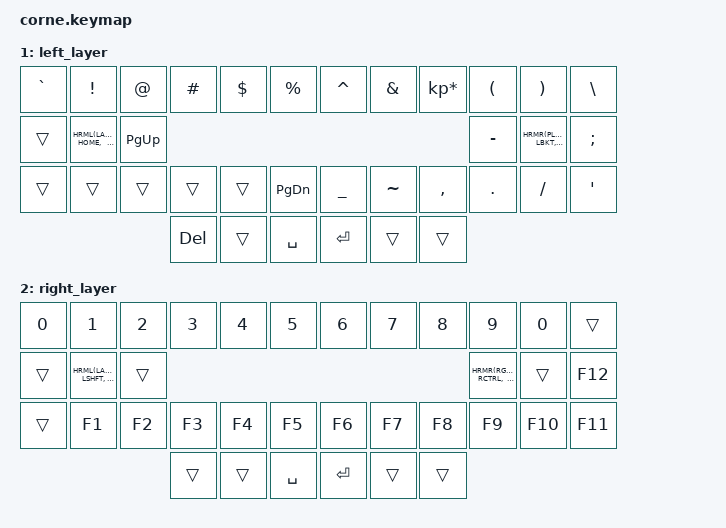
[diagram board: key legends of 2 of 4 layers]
/*
 * Copyright (c) 2020 The ZMK Contributors
 *
 * SPDX-License-Identifier: MIT
 */

#include <behaviors.dtsi>
#include <dt-bindings/zmk/keys.h>
#include <dt-bindings/zmk/bt.h>

#define L_DEFAULT 0
#define L_LEFT    1
#define L_RIGHT   2
#define L_SPECIAL 3

#define HRML(k1, k2, k3, k4) &ht LALT k1  &ht LCTRL k2  &ht LSHFT k3  &ht LGUI k4
#define HRMR(k1, k2, k3, k4) &ht RGUI k1  &ht RSHFT k2  &ht RCTRL k3  &ht RALT k4
#define HRMRR(k1, k2, k3) &ht RGUI k1  &ht RSHFT k2  &ht RCTRL k3
//#define LRTL(k) &layert L_LEFT k

&key_repeat {
	usage-pages = <HID_USAGE_KEY HID_USAGE_CONSUMER>;
};

/ {
    	behaviors {
        	ht: hold_tap {
            		compatible = "zmk,behavior-hold-tap";
            		label = "HOLD_TAP";
            		#binding-cells = <2>;
            		flavor = "tap-preferred";
            		tapping-term-ms = <220>;
            		quick-tap-ms = <150>;
			global-quick-tap;
            		bindings = <&kp>, <&kp>;
        	};
/*
        	layert: layer_tap {
            		compatible = "zmk,behavior-hold-tap";
            		label = "LAYER_TAP";
            		#binding-cells = <2>;
            		flavor = "tap-preferred";
            		tapping-term-ms = <220>;
            		quick-tap-ms = <150>;
			global-quick-tap;
            		bindings = <&mo>, <&kp>;
        	};
*/
                td_rep: tap_dance_repeat {
                        compatible = "zmk,behavior-tap-dance";
                        label = "TD_REPEAT";
                        #binding-cells = <0>;
                        tapping-term-ms = <220>;
                        bindings = <&kp RCTRL>, <&key_repeat>;
                };
                td_gui: tap_dance_gui {
                        compatible = "zmk,behavior-tap-dance";
                        label = "TD_GUI";
                        #binding-cells = <0>;
                        tapping-term-ms = <300>;
                        bindings = <&kp LGUI>, <&mo L_SPECIAL>;
                };
                td_l: tap_dance_l {
                        compatible = "zmk,behavior-tap-dance";
                        label = "TD_LEFT";
                        #binding-cells = <0>;
                        tapping-term-ms = <300>;
                        bindings = <&mo L_LEFT>, <&mo L_SPECIAL>;
                };
                td_r: tap_dance_r {
                        compatible = "zmk,behavior-tap-dance";
                        label = "TD_RIGHT";
                        #binding-cells = <0>;
                        tapping-term-ms = <300>;
                        bindings = <&mo L_RIGHT>, <&mo L_SPECIAL>;
                };
                td_caps: tap_dance_caps {
                        compatible = "zmk,behavior-tap-dance";
                        label = "TD_CAPS_LOCK";
                        #binding-cells = <0>;
                        tapping-term-ms = <300>;
                        bindings = <&kp LSHFT>, <&kp CAPS>;
                };

    	};

    	combos {
        	compatible = "zmk,combos";
	        combo_esc0 {
            		timeout-ms = <50>;
            		key-positions = <0 1>;
            		bindings = <&kp ESC>;
        	};
	        combo_esc1 {
            		timeout-ms = <50>;
            		key-positions = <1 2>;
            		bindings = <&kp ESC>;
        	};
		combo_esc2 {
            		timeout-ms = <50>;
            		key-positions = <4 5>;
            		bindings = <&kp ESC>;
        	};
    	};

/*
    	macros {
        	macro_n: macro_n {
	            label = "MACRO_N";
        	    compatible = "zmk,behavior-macro";
	            #binding-cells = <0>;
        	    bindings
	                = <&macro_press &kp RALT>
			, <&macro_tap &kp N>
			, <&macro_release &kp RALT>
			, <&macro_tap &kp N>
	                ;
        	};
        	macro_tilde: macro_tilde {
	            label = "MACRO_TILDE";
        	    compatible = "zmk,behavior-macro";
	            #binding-cells = <0>;
        	    bindings
	                = <&macro_press &kp RALT>
			, <&macro_tap &kp E>
			, <&macro_release &kp RALT>
	                ;
        	};
        	macro_0: macro_0 {
	            label = "MACRO_0";
        	    compatible = "zmk,behavior-macro";
	            #binding-cells = <0>;
        	    bindings
	                = <&macro_press &kp LGUI>
			, <&macro_tap &kp GRAVE>
			, <&macro_release &kp LGUI>
	                ;
        	};
        	macro_vim_w: macro_vim_w {
	            label = "MACRO_W";
        	    compatible = "zmk,behavior-macro";
	            #binding-cells = <0>;
        	    bindings
	                = <&macro_tap &kp COLON>
			, <&macro_tap &kp W>
	                ;
        	};
        	macro_vim_q: macro_vim_q {
	            label = "MACRO_Q";
        	    compatible = "zmk,behavior-macro";
	            #binding-cells = <0>;
        	    bindings
	                = <&macro_tap &kp COLON>
			, <&macro_tap &kp Q>
	                ;
        	};

	};
*/

        keymap {
                compatible = "zmk,keymap";

                default_layer {
                        bindings = <
//  ----------------------------------------------------------     --------------------------------------------------------------------
// |   TAB     |  Q     |  W     |  E      |  R     |  T      |   |  Y     |  U      |  I         |  O        |  P          | \        |                        
     &kp TAB      &kp Q   &kp W     &kp E     &kp R    &kp T         &kp Y    &kp U     &kp I        &kp O       &kp P        &kp BSLH
// |----------------------------------------------------------     --------------------------------------------------------------------|
// | SHIFT / CAPS |  A  |  S     |  D      |  F     |  G      |   |  H     |  J      |  K         |  L        |  UP         |  ;       |
     &td_caps    HRML(A,   S,       D,        F)       &kp G         &kp H   HRMRR(J,    K,           L)         &kp UP       &kp SEMI
// |----------------------------------------------------------     --------------------------------------------------------------------|   
// | CTRL      |  Z     |  X     |  C      |  V     |  B      |   |  N     |  M      |  ,         |  LEFT     | DOWN        | RIGHT    |
     &td_rep     &kp Z    &kp X    &kp C     &kp V    &kp B         &kp N    &kp M     &kp COMMA     &kp LEFT    &kp DOWN     &kp RIGHT
// |----------------------------------------------------------     --------------------------------------------------------------------|     
//                          | GUI / SPECIAL | LAYERS | SPC    |   | ENT    | LAYERS  | BSPC      |
                                  &td_gui     &td_l   &kp SPACE    &kp RET  &td_r     &kp BSPC
                        >;
                };

                left_layer {
                        bindings = <
//  ----------------------------------------------------------------------     -------------------------------------------------------------------------  
// |  `          |  !        |  @       |  #       |  $       |  %        |   |  ^        |  &       |  *              |  (       |  )       |  \       |                        
      &kp GRAVE     &kp EXCL    &kp AT    &kp HASH   &kp DLLR   &kp PRCNT       &kp CARET   &kp AMPS   &kp KP_MULTIPLY   &kp LPAR   &kp RPAR   &kp BSLH
//  ----------------------------------------------------------------------     -------------------------------------------------------------------------      
// |             |           |          | HOME     | END      | PAGE_UP   |   |  -        |  +       |  =              |  [       |  ]       | ;        |
     &trans     HRML(LALT,      LCTRL,    HOME,      END)       &kp PG_UP       &kp MINUS  HRMR(PLUS,   EQUAL,            LBKT,      RBKT)     &kp SEMI
//  ----------------------------------------------------------------------     -------------------------------------------------------------------------     
// |             |           |          |          |          | PAGE_DOWN |   |  _        |  ~       |  ,              |  .       |  /       |  '       |
     &trans         &trans      &trans    &trans     &trans     &kp PG_DN       &kp UNDER   &kp TILDE   &kp COMMA         &kp DOT   &kp FSLH   &kp SQT
//  ----------------------------------------------------------------------     -------------------------------------------------------------------------        
//                                      | DEL      | XXXXXXX  | SPC       |   | ENT       |          |                 |   
                    	                  &kp DEL    &trans     &kp SPACE       &kp RET     &trans     &trans
                        >;
                };

                right_layer {
                        bindings = <
//  ----------------------------------------------------------------------     -----------------------------------------------------------------  
// |  0         |  1        |  2        |  3      |  4        |  5        |   | 6        |  7       |  8       |  9        |  0      |          |
      &kp N0       &kp N1      &kp N2      &kp N3    &kp N4      &kp N5         &kp N6      &kp N7    &kp N8     &kp N9     &kp N0     &trans
//  ----------------------------------------------------------------------     -----------------------------------------------------------------  
// |            |           |           |         |           |           |   |          |          |          |           |         | F12      |   
     &trans    HRML(LALT,      LCTRL,      LSHFT,    LGUI)      &trans        HRMR(RGUI,   RSHFT,     RCTRL,     RALT)       &trans   &kp F12
//  ----------------------------------------------------------------------     -----------------------------------------------------------------     
// |            | F1        | F2        | F3      | F4        |  F5       |   | F6       | F7       | F8       | F9        | F10     | F11      |   
     &trans       &kp F1      &kp F2      &kp F3    &kp F4       &kp F5         &kp F6     &kp F7     &kp F8     &kp F9      &kp F10   &kp F11
//  ----------------------------------------------------------------------     -----------------------------------------------------------------          
//                                      |         |           |  SPC      |   | ENT      | XXXXXXX  |          |
                                       	  &trans     &trans      &kp SPACE      &kp RET    &trans     &trans 
                        >;
                };

                special_layer {
                        bindings = <
//  ----------------------------------------------------------------------     -------------------------------------------------------------------------  
// |  GUI+`      |           |  +       | 7        | 8        | 9         |    | F1       | F4       | F7              | F10      |          | MUTE     |                      
      &kp LG(GRAVE) &trans      &kp PLUS  &kp N7     &kp N8     &kp N9          &kp F1      &kp F4     &kp F7            &kp F10    &trans     &kp K_MUTE
//  ----------------------------------------------------------------------     -------------------------------------------------------------------------      
// | + BRIGHT    |           |  -       | 4        | 5        | 6         |   | F2        | F5       | F8              | F11      |          | + VOL    |
     &kp C_BRI_UP   &trans      &kp MINUS  &kp N4    &kp N5     &kp N6          &kp F2      &kp F5     &kp F8            &kp F11    &trans     &kp C_VOL_UP
//  ----------------------------------------------------------------------     -------------------------------------------------------------------------     
// | - BRIGHT    |           |  *       | 1        | 2        | 3         |   | F3        | F6       | F9              | F12      |          | - VOL    |
     &kp C_BRI_DN   &trans  &kp KP_MULTIPLY &kp N1   &kp N2     &kp N3          &kp F3       &kp F6    &kp F9            &kp F12    &trans     &kp C_VOL_DN
//  ----------------------------------------------------------------------     -------------------------------------------------------------------------        
//                                      | 0        | XXXXX    | SPC       |   | ENT       | XXXXXXXX |                 |   
                    	                  &kp N0     &trans     &kp SPACE       &kp RET     &trans     &trans
                        >;
                };

        };
};
